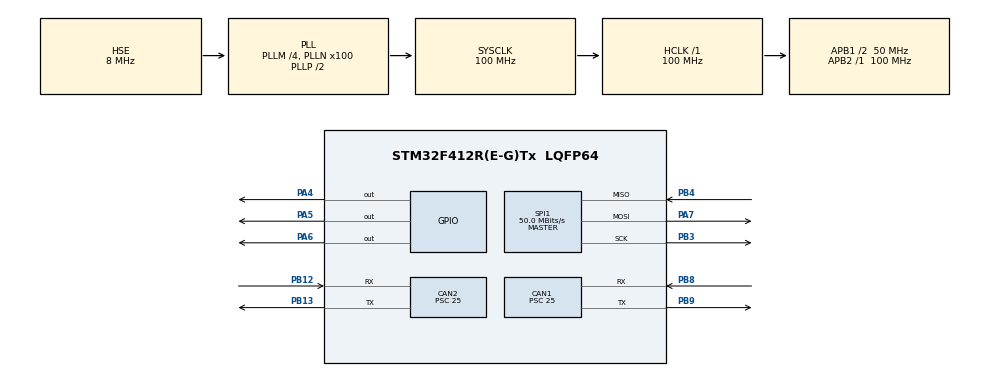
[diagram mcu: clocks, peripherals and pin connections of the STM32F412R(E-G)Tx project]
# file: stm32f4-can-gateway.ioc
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CAN1.ABOM=ENABLE
CAN1.AWUM=ENABLE
CAN1.BS1=CAN_BS1_6TQ
CAN1.CalculateBaudRate=250000
CAN1.CalculateTimeBit=4000
CAN1.CalculateTimeQuantum=500.0
CAN1.Mode=CAN_MODE_NORMAL
CAN1.NART=DISABLE
CAN1.Prescaler=25
CAN1.RFLM=DISABLE
CAN1.SJW=CAN_SJW_1TQ
CAN1.TTCM=DISABLE
CAN1.TXFP=DISABLE
CAN2.ABOM=ENABLE
CAN2.AWUM=ENABLE
CAN2.BS1=CAN_BS1_6TQ
CAN2.CalculateBaudRate=250000
CAN2.CalculateTimeBit=4000
CAN2.CalculateTimeQuantum=500.0
CAN2.Mode=CAN_MODE_NORMAL
CAN2.NART=DISABLE
CAN2.Prescaler=25
CAN2.RFLM=DISABLE
CAN2.SJW=CAN_SJW_1TQ
CAN2.TTCM=DISABLE
CAN2.TXFP=DISABLE
Mcu.Family=STM32F4
Mcu.Name=STM32F412R(E-G)Tx
Mcu.Package=LQFP64
NVIC.CAN1_RX0_IRQn=true\:0\:0\:false\:false\:true\:true\:true\:true
NVIC.CAN1_RX1_IRQn=true\:0\:0\:false\:false\:true\:true\:true\:true
NVIC.CAN1_SCE_IRQn=true\:0\:0\:false\:false\:true\:true\:true\:true
NVIC.CAN1_TX_IRQn=true\:0\:0\:false\:false\:true\:true\:true\:true
NVIC.CAN2_RX0_IRQn=true\:0\:0\:false\:false\:true\:true\:true\:true
NVIC.CAN2_RX1_IRQn=true\:0\:0\:false\:false\:true\:true\:true\:true
NVIC.CAN2_SCE_IRQn=true\:0\:0\:false\:false\:true\:true\:true\:true
NVIC.CAN2_TX_IRQn=true\:0\:0\:false\:false\:true\:true\:true\:true
NVIC.PriorityGroup=NVIC_PRIORITYGROUP_4
PA10.Signal=USART1_RX
PA13.Mode=Serial_Wire
PA13.Signal=SYS_JTMS-SWDIO
PA14.Mode=Serial_Wire
PA14.Signal=SYS_JTCK-SWCLK
PA2.Signal=USART2_TX
PA4.Signal=GPIO_Output
PA5.Signal=GPIO_Output
PA6.Signal=GPIO_Output
PA7.Mode=Full_Duplex_Master
PA7.Signal=SPI1_MOSI
PA9.Signal=USART1_TX
PB12.Mode=CAN_Activate
PB12.Signal=CAN2_RX
PB13.Mode=CAN_Activate
PB13.Signal=CAN2_TX
PB3.Mode=Full_Duplex_Master
PB3.Signal=SPI1_SCK
PB4.Mode=Full_Duplex_Master
PB4.Signal=SPI1_MISO
PB8.Mode=CAN_Activate
PB8.Signal=CAN1_RX
PB9.Mode=CAN_Activate
PB9.Signal=CAN1_TX
PC14-OSC32_IN.Mode=LSE-External-Oscillator
PC14-OSC32_IN.Signal=RCC_OSC32_IN
PC15-OSC32_OUT.Mode=LSE-External-Oscillator
PC15-OSC32_OUT.Signal=RCC_OSC32_OUT
PH0\ -\ OSC_IN.Mode=HSE-External-Oscillator
PH0\ -\ OSC_IN.Signal=RCC_OSC_IN
PH1\ -\ OSC_OUT.Mode=HSE-External-Oscillator
PH1\ -\ OSC_OUT.Signal=RCC_OSC_OUT
ProjectManager.HeapSize=0x200
ProjectManager.StackSize=0x400
ProjectManager.TargetToolchain=CMake
RCC.AHBFreq_Value=100000000
RCC.APB1CLKDivider=RCC_HCLK_DIV2
RCC.APB1Freq_Value=50000000
RCC.APB1TimFreq_Value=100000000
RCC.APB2Freq_Value=100000000
RCC.APB2TimFreq_Value=100000000
RCC.CortexFreq_Value=100000000
RCC.HCLKFreq_Value=100000000
RCC.HSE_VALUE=8000000
RCC.PLLM=4
RCC.PLLN=100
RCC.PLLSourceVirtual=RCC_PLLSOURCE_HSE
RCC.PWR_Regulator_Voltage_Scale=PWR_REGULATOR_VOLTAGE_SCALE1
RCC.SYSCLKFreq_VALUE=100000000
RCC.SYSCLKSource=RCC_SYSCLKSOURCE_PLLCLK
RCC.USBFreq_Value=100000000
RCC.VCOOutputFreq_Value=200000000
SPI1.BaudRatePrescaler=SPI_BAUDRATEPRESCALER_2
SPI1.CalculateBaudRate=50.0 MBits/s
SPI1.Direction=SPI_DIRECTION_2LINES
SPI1.Mode=SPI_MODE_MASTER
SPI1.VirtualType=VM_MASTER
board=custom

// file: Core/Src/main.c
/* USER CODE BEGIN Header */
/**
  ******************************************************************************
  * @file           : main.c
  * @brief          : Main program body
  ******************************************************************************
  * @attention
  *
  * Copyright (c) 2026 STMicroelectronics.
  * All rights reserved.
  *
  * This software is licensed under terms that can be found in the LICENSE file
  * in the root directory of this software component.
  * If no LICENSE file comes with this software, it is provided AS-IS.
  *
  ******************************************************************************
  */
/* USER CODE END Header */
#include "main.h"

/* USER CODE BEGIN Includes */
#include "gateway.h"
// #include "tests.h"
/* USER CODE END Includes */

CAN_HandleTypeDef hcan1;
CAN_HandleTypeDef hcan2;

SPI_HandleTypeDef hspi1;

void SystemClock_Config(void);
static void MX_GPIO_Init(void);
static void MX_CAN1_Init(void);
static void MX_CAN2_Init(void);
static void MX_SPI1_Init(void);

int main(void)
{

  /* MCU Configuration--------------------------------------------------------*/

  /* Reset of all peripherals, Initializes the Flash interface and the Systick. */
  HAL_Init();

  /* Configure the system clock */
  SystemClock_Config();

  /* Initialize all configured peripherals */
  MX_GPIO_Init();
  MX_CAN1_Init();
  MX_CAN2_Init();
  MX_SPI1_Init();
  /* USER CODE BEGIN 2 */
  // Test_RunAll();   /* <<< hardware self-tests — inspect g_tests in debugger */
  Gateway_Init();
  Gateway_CAN_Init(&hcan1, &hcan2);
  Gateway_CAN_Start();
//  Gateway_LIN_Init(&huart1, &huart2);
  if (Gateway_InitOptionalMCP2515() == 0U)
  {
    Error_Handler();
  }
  /* USER CODE END 2 */

  /* Infinite loop */
  while (1)
  {

    /* USER CODE BEGIN 3 */
    Gateway_Process();
  }
  /* USER CODE END 3 */
}

void SystemClock_Config(void)
{
  RCC_OscInitTypeDef RCC_OscInitStruct = {0};
  RCC_ClkInitTypeDef RCC_ClkInitStruct = {0};

  /** Configure the main internal regulator output voltage
  */
  __HAL_RCC_PWR_CLK_ENABLE();
  __HAL_PWR_VOLTAGESCALING_CONFIG(PWR_REGULATOR_VOLTAGE_SCALE1);

  /** Initializes the RCC Oscillators according to the specified parameters
  * in the RCC_OscInitTypeDef structure.
  */
  RCC_OscInitStruct.OscillatorType = RCC_OSCILLATORTYPE_HSE;
  RCC_OscInitStruct.HSEState = RCC_HSE_ON;
  RCC_OscInitStruct.PLL.PLLState = RCC_PLL_ON;
  RCC_OscInitStruct.PLL.PLLSource = RCC_PLLSOURCE_HSE;
  RCC_OscInitStruct.PLL.PLLM = 4;
  RCC_OscInitStruct.PLL.PLLN = 100;
  RCC_OscInitStruct.PLL.PLLP = RCC_PLLP_DIV2;
  RCC_OscInitStruct.PLL.PLLQ = 2;
  RCC_OscInitStruct.PLL.PLLR = 2;
  if (HAL_RCC_OscConfig(&RCC_OscInitStruct) != HAL_OK)
  {
    Error_Handler();
  }

  /** Initializes the CPU, AHB and APB buses clocks
  */
  RCC_ClkInitStruct.ClockType = RCC_CLOCKTYPE_HCLK|RCC_CLOCKTYPE_SYSCLK
                              |RCC_CLOCKTYPE_PCLK1|RCC_CLOCKTYPE_PCLK2;
  RCC_ClkInitStruct.SYSCLKSource = RCC_SYSCLKSOURCE_PLLCLK;
  RCC_ClkInitStruct.AHBCLKDivider = RCC_SYSCLK_DIV1;
  RCC_ClkInitStruct.APB1CLKDivider = RCC_HCLK_DIV2;
  RCC_ClkInitStruct.APB2CLKDivider = RCC_HCLK_DIV1;

  if (HAL_RCC_ClockConfig(&RCC_ClkInitStruct, FLASH_LATENCY_3) != HAL_OK)
  {
    Error_Handler();
  }
}

static void MX_CAN1_Init(void)
{

  hcan1.Instance = CAN1;
  hcan1.Init.Prescaler = 25;
  hcan1.Init.Mode = CAN_MODE_NORMAL;
  hcan1.Init.SyncJumpWidth = CAN_SJW_1TQ;
  hcan1.Init.TimeSeg1 = CAN_BS1_6TQ;
  hcan1.Init.TimeSeg2 = CAN_BS2_1TQ;
  hcan1.Init.TimeTriggeredMode = DISABLE;
  hcan1.Init.AutoBusOff = ENABLE;
  hcan1.Init.AutoWakeUp = ENABLE;
  hcan1.Init.AutoRetransmission = DISABLE;
  hcan1.Init.ReceiveFifoLocked = DISABLE;
  hcan1.Init.TransmitFifoPriority = DISABLE;
  if (HAL_CAN_Init(&hcan1) != HAL_OK)
  {
    Error_Handler();
  }

}

static void MX_CAN2_Init(void)
{

  hcan2.Instance = CAN2;
  hcan2.Init.Prescaler = 25;
  hcan2.Init.Mode = CAN_MODE_NORMAL;
  hcan2.Init.SyncJumpWidth = CAN_SJW_1TQ;
  hcan2.Init.TimeSeg1 = CAN_BS1_6TQ;
  hcan2.Init.TimeSeg2 = CAN_BS2_1TQ;
  hcan2.Init.TimeTriggeredMode = DISABLE;
  hcan2.Init.AutoBusOff = ENABLE;
  hcan2.Init.AutoWakeUp = ENABLE;
  hcan2.Init.AutoRetransmission = DISABLE;
  hcan2.Init.ReceiveFifoLocked = DISABLE;
  hcan2.Init.TransmitFifoPriority = DISABLE;
  if (HAL_CAN_Init(&hcan2) != HAL_OK)
  {
    Error_Handler();
  }

}

static void MX_SPI1_Init(void)
{

  /* SPI1 parameter configuration*/
  hspi1.Instance = SPI1;
  hspi1.Init.Mode = SPI_MODE_MASTER;
  hspi1.Init.Direction = SPI_DIRECTION_2LINES;
  hspi1.Init.DataSize = SPI_DATASIZE_8BIT;
  hspi1.Init.CLKPolarity = SPI_POLARITY_LOW;
  hspi1.Init.CLKPhase = SPI_PHASE_1EDGE;
  hspi1.Init.NSS = SPI_NSS_SOFT;
  hspi1.Init.BaudRatePrescaler = SPI_BAUDRATEPRESCALER_2;
  hspi1.Init.FirstBit = SPI_FIRSTBIT_MSB;
  hspi1.Init.TIMode = SPI_TIMODE_DISABLE;
  hspi1.Init.CRCCalculation = SPI_CRCCALCULATION_DISABLE;
  hspi1.Init.CRCPolynomial = 10;
  if (HAL_SPI_Init(&hspi1) != HAL_OK)
  {
    Error_Handler();
  }

}

static void MX_GPIO_Init(void)
{
  GPIO_InitTypeDef GPIO_InitStruct = {0};

  /* GPIO Ports Clock Enable */
  __HAL_RCC_GPIOC_CLK_ENABLE();
  __HAL_RCC_GPIOH_CLK_ENABLE();
  __HAL_RCC_GPIOA_CLK_ENABLE();
  __HAL_RCC_GPIOB_CLK_ENABLE();

  /*Configure GPIO pin Output Level */
  HAL_GPIO_WritePin(GPIOA, GPIO_PIN_4|GPIO_PIN_5|GPIO_PIN_6, GPIO_PIN_RESET);

  /*Configure GPIO pin : PA2 */
  GPIO_InitStruct.Pin = GPIO_PIN_2;
  GPIO_InitStruct.Mode = GPIO_MODE_AF_PP;
  GPIO_InitStruct.Pull = GPIO_NOPULL;
  GPIO_InitStruct.Speed = GPIO_SPEED_FREQ_VERY_HIGH;
  GPIO_InitStruct.Alternate = GPIO_AF7_USART2;
  HAL_GPIO_Init(GPIOA, &GPIO_InitStruct);

  /*Configure GPIO pins : PA4 PA5 PA6 */
  GPIO_InitStruct.Pin = GPIO_PIN_4|GPIO_PIN_5|GPIO_PIN_6;
  GPIO_InitStruct.Mode = GPIO_MODE_OUTPUT_PP;
  GPIO_InitStruct.Pull = GPIO_NOPULL;
  GPIO_InitStruct.Speed = GPIO_SPEED_FREQ_LOW;
  HAL_GPIO_Init(GPIOA, &GPIO_InitStruct);

  /*Configure GPIO pins : PA9 PA10 */
  GPIO_InitStruct.Pin = GPIO_PIN_9|GPIO_PIN_10;
  GPIO_InitStruct.Mode = GPIO_MODE_AF_PP;
  GPIO_InitStruct.Pull = GPIO_NOPULL;
  GPIO_InitStruct.Speed = GPIO_SPEED_FREQ_VERY_HIGH;
  GPIO_InitStruct.Alternate = GPIO_AF7_USART1;
  HAL_GPIO_Init(GPIOA, &GPIO_InitStruct);

}

void Error_Handler(void)
{
  __disable_irq();
  while (1)
  {
  }
}
